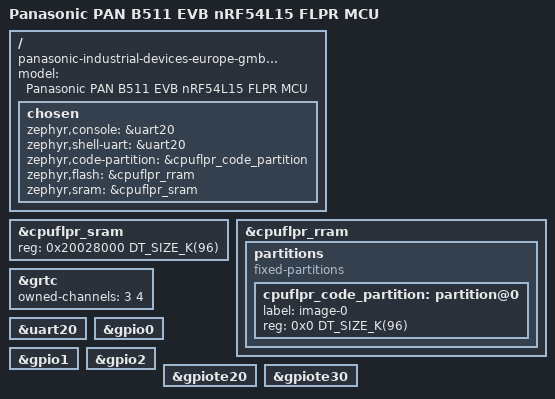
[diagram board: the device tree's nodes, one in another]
/*
 * Copyright (c) 2025 Panasonic Industrial Devices Europe GmbH
 *
 * SPDX-License-Identifier: Apache-2.0
 */

/dts-v1/;
#include <nordic/nrf54l15_cpuflpr.dtsi>
#include "panb511evb_nrf54l15_common.dtsi"

/ {
	model = "Panasonic PAN B511 EVB nRF54L15 FLPR MCU";
	compatible = "panasonic-industrial-devices-europe-gmbh,panb511evb-cpuflpr";

	chosen {
		zephyr,console = &uart20;
		zephyr,shell-uart = &uart20;
		zephyr,code-partition = &cpuflpr_code_partition;
		zephyr,flash = &cpuflpr_rram;
		zephyr,sram = &cpuflpr_sram;
	};
};

&cpuflpr_sram {
	status = "okay";
	/* Size must be increased due to booting from SRAM */
	reg = <0x20028000 DT_SIZE_K(96)>;
	ranges = <0x0 0x20028000 0x18000>;
};

&cpuflpr_rram {
	partitions {
		compatible = "fixed-partitions";
		#address-cells = <1>;
		#size-cells = <1>;

		cpuflpr_code_partition: partition@0 {
			label = "image-0";
			reg = <0x0 DT_SIZE_K(96)>;
		};
	};
};

&grtc {
	owned-channels = <3 4>;
	status = "okay";
};

&uart20 {
	status = "okay";
};

&gpio0 {
	status = "okay";
};

&gpio1 {
	status = "okay";
};

&gpio2 {
	status = "okay";
};

&gpiote20 {
	status = "okay";
};

&gpiote30 {
	status = "okay";
};
